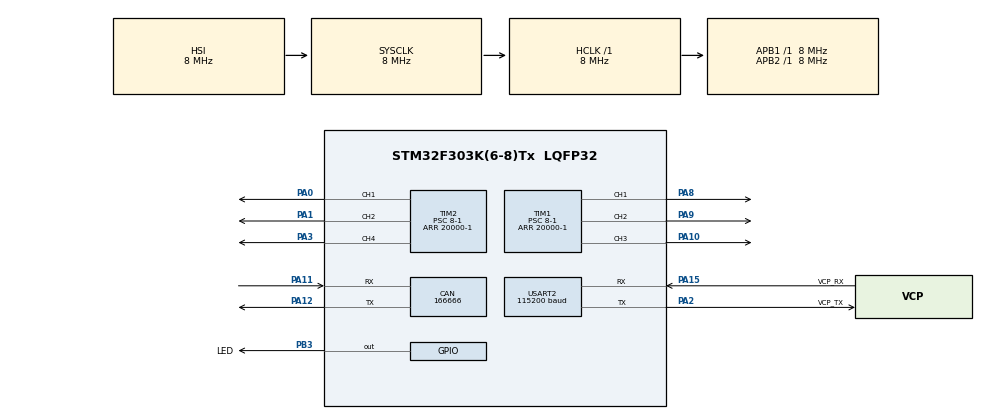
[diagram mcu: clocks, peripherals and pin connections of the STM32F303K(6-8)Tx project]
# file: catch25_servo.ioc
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CAN.CalculateBaudRate=166666
CAN.CalculateTimeBit=6000
CAN.CalculateTimeQuantum=2000.0
Mcu.Family=STM32F3
Mcu.Name=STM32F303K(6-8)Tx
Mcu.Package=LQFP32
NVIC.PriorityGroup=NVIC_PRIORITYGROUP_4
NVIC.USART2_IRQn=true\:0\:0\:false\:false\:true\:true\:true\:true
PA0.Signal=S_TIM2_CH1_ETR
PA1.Signal=S_TIM2_CH2
PA10.Signal=S_TIM1_CH3
PA11.Mode=CAN_Activate
PA11.Signal=CAN_RX
PA12.Mode=CAN_Activate
PA12.Signal=CAN_TX
PA13.GPIO_Label=SWDIO
PA13.Mode=Serial_Wire
PA13.Signal=SYS_JTMS-SWDIO
PA14.GPIO_Label=SWCLK
PA14.Mode=Serial_Wire
PA14.Signal=SYS_JTCK-SWCLK
PA15.GPIO_Label=VCP_RX
PA15.Mode=Asynchronous
PA15.Signal=USART2_RX
PA2.GPIO_Label=VCP_TX
PA2.Mode=Asynchronous
PA2.Signal=USART2_TX
PA3.Signal=S_TIM2_CH4
PA8.Signal=S_TIM1_CH1
PA9.Signal=S_TIM1_CH2
PB3.GPIO_Label=LED
PB3.Signal=GPIO_Output
PB6.Signal=I2C1_SCL
PB7.Signal=I2C1_SDA
PF0\ /\ OSC_IN.GPIO_Label=MCO
PF0\ /\ OSC_IN.Mode=HSE-External-Clock-Source
PF0\ /\ OSC_IN.Signal=RCC_OSC_IN
ProjectManager.HeapSize=0x200
ProjectManager.StackSize=0x400
ProjectManager.TargetToolchain=CMake
RCC.AHBFreq_Value=8000000
RCC.APB1Freq_Value=8000000
RCC.APB2Freq_Value=8000000
RCC.CortexFreq_Value=8000000
RCC.HSE_VALUE=8000000
RCC.HSI_VALUE=8000000
RCC.SYSCLKFreq_VALUE=8000000
SH.S_TIM1_CH1.0=TIM1_CH1,PWM Generation1 CH1
SH.S_TIM1_CH2.0=TIM1_CH2,PWM Generation2 CH2
SH.S_TIM1_CH3.0=TIM1_CH3,PWM Generation3 CH3
SH.S_TIM2_CH1_ETR.0=TIM2_CH1,PWM Generation1 CH1
SH.S_TIM2_CH2.0=TIM2_CH2,PWM Generation2 CH2
SH.S_TIM2_CH4.0=TIM2_CH4,PWM Generation4 CH4
TIM1.Channel-PWM\ Generation1\ CH1=TIM_CHANNEL_1
TIM1.Channel-PWM\ Generation2\ CH2=TIM_CHANNEL_2
TIM1.Channel-PWM\ Generation3\ CH3=TIM_CHANNEL_3
TIM1.Period=20000-1
TIM1.Prescaler=8-1
TIM2.Channel-PWM\ Generation1\ CH1=TIM_CHANNEL_1
TIM2.Channel-PWM\ Generation2\ CH2=TIM_CHANNEL_2
TIM2.Channel-PWM\ Generation4\ CH4=TIM_CHANNEL_4
TIM2.Period=20000-1
TIM2.Prescaler=8-1
USART2.BaudRate=115200
USART2.VirtualMode-Asynchronous=VM_ASYNC
board=NUCLEO-F303K8

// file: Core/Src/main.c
/* USER CODE BEGIN Header */
/**
  ******************************************************************************
  * @file           : main.c
  * @brief          : Main program body
  ******************************************************************************
  * @attention
  *
  * Copyright (c) 2025 STMicroelectronics.
  * All rights reserved.
  *
  * This software is licensed under terms that can be found in the LICENSE file
  * in the root directory of this software component.
  * If no LICENSE file comes with this software, it is provided AS-IS.
  *
  ******************************************************************************
  */
/* USER CODE END Header */
#include "main.h"
#include "can.h"
#include "tim.h"
#include "usart.h"
#include "gpio.h"

/* USER CODE BEGIN Includes */
#include "main.hpp"

#include <string.h>
/* USER CODE END Includes */

void SystemClock_Config(void);

int main(void)
{

  /* MCU Configuration--------------------------------------------------------*/

  /* Reset of all peripherals, Initializes the Flash interface and the Systick. */
  HAL_Init();

  /* Configure the system clock */
  SystemClock_Config();

  /* Initialize all configured peripherals */
  MX_GPIO_Init();
  MX_USART2_UART_Init();
  MX_TIM2_Init();
  MX_CAN_Init();
  MX_TIM1_Init();
  /* USER CODE BEGIN 2 */
  setup();
  /* USER CODE END 2 */

  /* Infinite loop */
  /* USER CODE BEGIN WHILE */
  while (1)
  {
    loop();
    /* USER CODE END WHILE */

  }
}

void SystemClock_Config(void)
{
  RCC_OscInitTypeDef RCC_OscInitStruct = {0};
  RCC_ClkInitTypeDef RCC_ClkInitStruct = {0};
  RCC_PeriphCLKInitTypeDef PeriphClkInit = {0};

  /** Initializes the RCC Oscillators according to the specified parameters
  * in the RCC_OscInitTypeDef structure.
  */
  RCC_OscInitStruct.OscillatorType = RCC_OSCILLATORTYPE_HSI;
  RCC_OscInitStruct.HSIState = RCC_HSI_ON;
  RCC_OscInitStruct.HSICalibrationValue = RCC_HSICALIBRATION_DEFAULT;
  RCC_OscInitStruct.PLL.PLLState = RCC_PLL_NONE;
  if (HAL_RCC_OscConfig(&RCC_OscInitStruct) != HAL_OK)
  {
    Error_Handler();
  }

  /** Initializes the CPU, AHB and APB buses clocks
  */
  RCC_ClkInitStruct.ClockType = RCC_CLOCKTYPE_HCLK|RCC_CLOCKTYPE_SYSCLK
                              |RCC_CLOCKTYPE_PCLK1|RCC_CLOCKTYPE_PCLK2;
  RCC_ClkInitStruct.SYSCLKSource = RCC_SYSCLKSOURCE_HSI;
  RCC_ClkInitStruct.AHBCLKDivider = RCC_SYSCLK_DIV1;
  RCC_ClkInitStruct.APB1CLKDivider = RCC_HCLK_DIV1;
  RCC_ClkInitStruct.APB2CLKDivider = RCC_HCLK_DIV1;

  if (HAL_RCC_ClockConfig(&RCC_ClkInitStruct, FLASH_LATENCY_0) != HAL_OK)
  {
    Error_Handler();
  }
  PeriphClkInit.PeriphClockSelection = RCC_PERIPHCLK_TIM1;
  PeriphClkInit.Tim1ClockSelection = RCC_TIM1CLK_HCLK;
  if (HAL_RCCEx_PeriphCLKConfig(&PeriphClkInit) != HAL_OK)
  {
    Error_Handler();
  }
}

void Error_Handler(void)
{
  __disable_irq();
  while (1)
  {
  }
}
